AUTOSAR XML (schema 4-2-1)
package /ComponentTypes
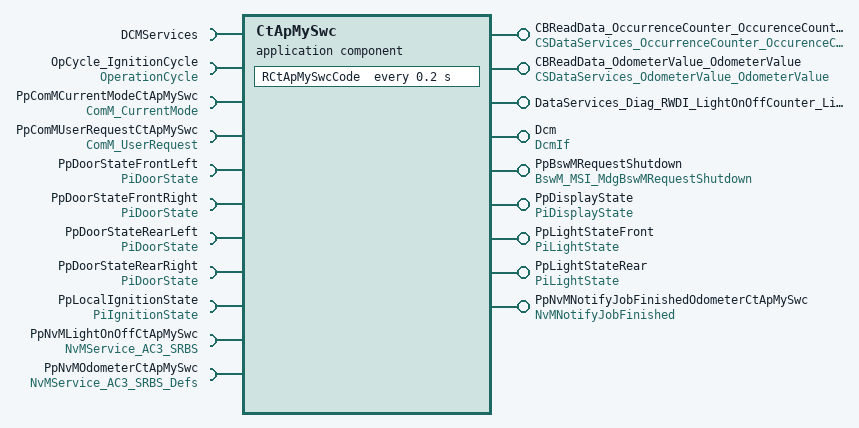
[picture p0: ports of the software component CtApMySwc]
  application sw component type CtApMySwc
    9 x provide port:
      CBReadData_OccurrenceCounter_OccurenceCounter: server-com-spec{operation=ReadData, queue-length=1}, provided-interface=CSDataServices_OccurrenceCounter_OccurenceCounter
      CBReadData_OdometerValue_OdometerValue: server-com-spec{operation=ReadData, queue-length=1}, provided-interface=CSDataServices_OdometerValue_OdometerValue
      DataServices_Diag_RWDI_LightOnOffCounter_LightOnOffCounter_Value: provided-interface=DataServices_Diag_RWDI_LightOnOffCounter_LightOnOffCounter_Value
        provided-com-specs:
          operation=ConditionCheckRead, queue-length=1
          operation=ReadData, queue-length=1
          operation=WriteData, queue-length=1
      Dcm: provided-interface=DcmIf
        provided-com-specs:
          operation=DcmClearDTC, queue-length=1
          operation=DcmEnableDTCSetting, queue-length=1
          operation=DcmGetExtendedDataRecordByDTC, queue-length=1
      PpBswMRequestShutdown: mode-switch-sender-com-spec{enhanced-mode-api=false, mode-group=BswM_MDGP_MdgBswMRequestShutdown, queue-length=1}, provided-interface=BswM_MSI_MdgBswMRequestShutdown
      PpDisplayState: provided-interface=PiDisplayState
        provided-com-specs:
          data-element=DeDisplayBusState, init-value=constant-reference=CDisplayOff
          data-element=DeLightOnOffCounter, init-value=constant-reference=CUInt32Zero
          data-element=DeOdometerValue, init-value=constant-reference=CUInt32Zero
          data-element=DeOdometerWriteRequestPending, init-value=constant-reference=CWriteReqNotPending
      PpLightStateFront: nonqueued-sender-com-spec{data-element=DeLightState, init-value=constant-reference=CLightOff}, provided-interface=PiLightState
      PpLightStateRear: nonqueued-sender-com-spec{data-element=DeLightState, init-value=constant-reference=CLightOff}, provided-interface=PiLightState
      PpNvMNotifyJobFinishedOdometerCtApMySwc: server-com-spec{operation=JobFinished, queue-length=1}, provided-interface=NvMNotifyJobFinished
    11 x require port:
      DCMServices: required-interface=DCMServices
      OpCycle_IgnitionCycle: required-interface=OperationCycle
      PpComMCurrentModeCtApMySwc: mode-switch-receiver-com-spec{enhanced-mode-api=false, supports-asynchronous-mode-switch=false}, required-interface=ComM_CurrentMode
      PpComMUserRequestCtApMySwc: required-interface=ComM_UserRequest
      PpDoorStateFrontLeft: nonqueued-receiver-com-spec{data-element=DeDoorState, filter=data-filter-type=ALWAYS, init-value=constant-reference=CDoorClosed}, required-interface=PiDoorState
      PpDoorStateFrontRight: nonqueued-receiver-com-spec{data-element=DeDoorState, filter=data-filter-type=ALWAYS, init-value=constant-reference=CDoorClosed}, required-interface=PiDoorState
      PpDoorStateRearLeft: nonqueued-receiver-com-spec{data-element=DeDoorState, filter=data-filter-type=ALWAYS, init-value=constant-reference=CDoorClosed}, required-interface=PiDoorState
      PpDoorStateRearRight: nonqueued-receiver-com-spec{data-element=DeDoorState, filter=data-filter-type=ALWAYS, init-value=constant-reference=CDoorClosed}, required-interface=PiDoorState
      PpLocalIgnitionState: nonqueued-receiver-com-spec{data-element=DeIgnitionState, filter=data-filter-type=ALWAYS, init-value=0}, required-interface=PiIgnitionState
      PpNvMLightOnOffCtApMySwc: required-interface=NvMService_AC3_SRBS
      PpNvMOdometerCtApMySwc: required-interface=NvMService_AC3_SRBS_Defs
    behavior CtApMySwc_InternalBehavior: data-type-mapping=DemoTypeMapping
      exclusive area ExArLightOnOffCounter
      exclusive area ExArOdometer
      ar-typed-per-instance-memorys:
        data PimLightOnOffCounter: sw-calibration-access=READ-ONLY, type=AdtLightOnOffCounter
        data PimOdometer: sw-calibration-access=READ-ONLY, type=AdtOdometer
      operation invoked event OIT_CBReadData_OccurrenceCounter_OccurenceCounter_ReadData_CBReadData_OccurrenceCounter_OccurenceCounter_ReadData: start-on-event=CBReadData_OccurrenceCounter_OccurenceCounter_ReadData, operation=CBReadData_OccurrenceCounter_OccurenceCounter.ReadData
      operation invoked event OIT_CBReadData_OdometerValue_OdometerValue_ReadData_CBReadData_OdometerValue_OdometerValue_ReadData: start-on-event=CBReadData_OdometerValue_OdometerValue_ReadData, operation=CBReadData_OdometerValue_OdometerValue.ReadData
      init event CtApMySwc_InitEvent: start-on-event=CtApMySwc_Init
      4 x operation invoked event:
        OIT_DataServices_Diag_RWDI_LightOnOffCounter_LightOnOffCounter_Value_ConditionCheckRead_DataServices_Diag_RWDI_LightOnOf2065F94A: start-on-event=DataServices_Diag_RWDI_LightOnOffCounter_LightOnOffCounter_Value_ConditionCheckRead, operation=DataServices_Diag_RWDI_LightOnOffCounter_LightOnOffCounter_Value.ConditionCheckRead
        OIT_DataServices_Diag_RWDI_LightOnOffCounter_LightOnOffCounter_Value_ReadData_DataServices_Diag_RWDI_LightOnOffCounter_LBCB6C10A: start-on-event=DataServices_Diag_RWDI_LightOnOffCounter_LightOnOffCounter_Value_ReadData, operation=DataServices_Diag_RWDI_LightOnOffCounter_LightOnOffCounter_Value.ReadData
        OIT_DataServices_Diag_RWDI_LightOnOffCounter_LightOnOffCounter_Value_WriteData_DataServices_Diag_RWDI_LightOnOffCounter_9798F8A6: start-on-event=DataServices_Diag_RWDI_LightOnOffCounter_LightOnOffCounter_Value_WriteData, operation=DataServices_Diag_RWDI_LightOnOffCounter_LightOnOffCounter_Value.WriteData
        OIT_NvM_RpNotifyJobEnd_CpApMySwcSnNvMPimLightOnOffCounter_JobFinished_NvM_RpNotifyJobEnd_CpApMySwcSnNvMPimLightOnOffCoun0E0D6B8B: start-on-event=PpNvMNotifyJobFinishedOdometerCtApMySwc_JobFinished, operation=PpNvMNotifyJobFinishedOdometerCtApMySwc.JobFinished
      timing event TMT_RCtApMySwcCode: start-on-event=RCtApMySwcCode, period=0.2
      swc mode switch event MST_RCtApMySwcComM_ModeChange_FULL_COMM_Entry_0: start-on-event=RCtApMySwcComM_ModeChange_FULL_COMM_Entry, activation=ON-ENTRY, mode=PpComMCurrentModeCtApMySwc.currentMode.COMM_FULL_COMMUNICATION
      swc mode switch event MST_RCtApMySwcComM_ModeChange_FULL_COMM_Exit_0: start-on-event=RCtApMySwcComM_ModeChange_FULL_COMM_Exit, activation=ON-EXIT, mode=PpComMCurrentModeCtApMySwc.currentMode.COMM_FULL_COMMUNICATION
      explicit-inter-runnable-variables:
        data IrvDoorStateOld: type=AdtDoorState, init-value=constant-reference=CDoorClosed
      10 x runnable:
        CBReadData_OccurrenceCounter_OccurenceCounter_ReadData
        CBReadData_OdometerValue_OdometerValue_ReadData: can-enter-exclusive-area=ExArOdometer
        CtApMySwc_Init: can-enter-exclusive-area=ExArLightOnOffCounter
          data-send-points:
            access SEND_PpDisplayState_DeLightOnOffCounter: accessed-variable=PpDisplayState.DeLightOnOffCounter
          sync call SC_OpCycle_IgnitionCycle_SetOperationCycleState: operation=OpCycle_IgnitionCycle.SetOperationCycleState, timeout=0
        DataServices_Diag_RWDI_LightOnOffCounter_LightOnOffCounter_Value_ConditionCheckRead: can-enter-exclusive-area=ExArLightOnOffCounter
        DataServices_Diag_RWDI_LightOnOffCounter_LightOnOffCounter_Value_ReadData: can-enter-exclusive-area=ExArLightOnOffCounter
        DataServices_Diag_RWDI_LightOnOffCounter_LightOnOffCounter_Value_WriteData: can-enter-exclusive-area=ExArLightOnOffCounter
          sync call SC_PpNvMLightOnOffCtApMySwc_WriteBlock: operation=PpNvMLightOnOffCtApMySwc.WriteBlock, timeout=0
        PpNvMNotifyJobFinishedOdometerCtApMySwc_JobFinished
          data-send-points:
            access SEND_PpDisplayState_DeOdometerWriteRequestPending: accessed-variable=PpDisplayState.DeOdometerWriteRequestPending
        RCtApMySwcCode: can-enter-exclusive-area=[ExArLightOnOffCounter, ExArOdometer], mode-access-point=PpBswMRequestShutdown.BswM_MDGP_MdgBswMRequestShutdown
          data-read-access:
            access REC_PpDoorStateFrontLeft_Element: accessed-variable=PpDoorStateFrontLeft.DeDoorState
            access REC_PpDoorStateRearLeft_DeDoorState: accessed-variable=PpDoorStateRearLeft.DeDoorState
          data-receive-point-by-arguments:
            access REC_PpDoorStateFrontRight_Element: accessed-variable=PpDoorStateFrontRight.DeDoorState
            access REC_PpDoorStateRearRight_DeDoorState: accessed-variable=PpDoorStateRearRight.DeDoorState
            access REC_PpLocalIgnitionState_DeIgnitionState: accessed-variable=PpLocalIgnitionState.DeIgnitionState
          data-send-points:
            6 x access:
              SEND_PpDisplayState_DeDisplayBusState: accessed-variable=PpDisplayState.DeDisplayBusState
              SEND_PpDisplayState_DeLightOnOffCounter: accessed-variable=PpDisplayState.DeLightOnOffCounter
              SEND_PpDisplayState_DeOdometerValue: accessed-variable=PpDisplayState.DeOdometerValue
              SEND_PpDisplayState_DeOdometerWriteRequrestPending: accessed-variable=PpDisplayState.DeOdometerWriteRequestPending
              SEND_PpLightStateFront_Element: accessed-variable=PpLightStateFront.DeLightState
              SEND_PpLightStateRear_DeLightState: accessed-variable=PpLightStateRear.DeLightState
          mode switch point SWITCH_PpBswMRequestShutdown_BswM_MDGP_MdgBswMRequestShutdown: mode-group=PpBswMRequestShutdown.BswM_MDGP_MdgBswMRequestShutdown
          read-local-variables:
            access READ_IrvDoorStateOld: accessed-variable=IrvDoorStateOld
          4 x sync call, all with timeout=0:
            SC_PpComMUserRequestCtApMySwc_RequestComMode: operation=PpComMUserRequestCtApMySwc.RequestComMode
            SC_PpNvMLightOnOffCtApMySwc_WriteBlock: operation=PpNvMLightOnOffCtApMySwc.WriteBlock
            SC_PpNvMOdometer_WriteBlock: operation=PpNvMOdometerCtApMySwc.WriteBlock
            SC_PpNvMOdometerCtApMySwc_GetErrorStatus: operation=PpNvMOdometerCtApMySwc.GetErrorStatus
          written-local-variables:
            access WRITE_IrvDoorStateOld: accessed-variable=IrvDoorStateOld
        RCtApMySwcComM_ModeChange_FULL_COMM_Entry
          data-send-points:
            access SEND_PpDisplayState_DeDisplayBusState: accessed-variable=PpDisplayState.DeDisplayBusState
        RCtApMySwcComM_ModeChange_FULL_COMM_Exit
          data-send-points:
            access SEND_PpDisplayState_DeDisplayBusState: accessed-variable=PpDisplayState.DeDisplayBusState
      swc service dependency SnNvMPimLightOnOffCounter: assigned-datas=role-based-data-assignment={role=ramBlock, used-data-element=PimLightOnOffCounter}
        assigned-ports:
          port-prototype=PpNvMLightOnOffCtApMySwc, role=NvMService_AC3_SRBS
          port-prototype=PpNvMLightOnOffCtApMySwc, role=NvMService_AC3_SRBS
        service-needs:
          nv block needs SnNvMPimLightOnOffCounter: readonly=false, resistant-to-changed-sw=false, restore-at-start=true, store-at-shutdown=true, write-only-once=false
      swc service dependency SnNvM_PimOdometer
        assigned-datas:
          role=ramBlock, used-data-element=PimOdometer
          role=defaultValue, used-parameter-element=CalOdometer
        assigned-ports:
          port-prototype=PpNvMNotifyJobFinishedOdometerCtApMySwc, role=NvMNotifyJobFinished
          port-prototype=PpNvMOdometerCtApMySwc, role=NvMService_AC3_SRBS_Defs
          port-prototype=PpNvMNotifyJobFinishedOdometerCtApMySwc, role=NvMNotifyJobFinished
          port-prototype=PpNvMOdometerCtApMySwc, role=NvMService_AC3_SRBS_Defs
        service-needs:
          nv block needs SnNvM_PimOdometer: readonly=false, resistant-to-changed-sw=false, restore-at-start=true, store-at-shutdown=true, write-only-once=false
      shared-parameters:
        parameter data prototype CalOdometer: sw-calibration-access=READ-WRITE, type=AdtOdometer, init-value=constant-reference=COdometerDefault
  swc implementation CtApMySwc_Implementation: behavior=CtApMySwc_InternalBehavior
    code-descriptors:
      code Default: artifact-descriptors=autosar-engineering-object={short-label=Default, category=SWSRC}
